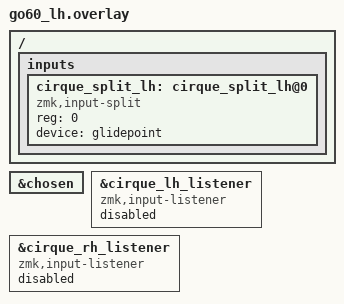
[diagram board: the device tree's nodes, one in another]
/ {
    
    inputs {
        cirque_split_lh: cirque_split_lh@0 {
            compatible = "zmk,input-split";
            reg = <0>;
            device = <&glidepoint>;
        };
    };
};

&chosen {
  /delete-property/ zmk,underglow_indicators;
}
/delete-node/ &underglow_indicators;
/delete-node/ &cirque_split;

// Disabled input listeners for the Cirques, to permit references in the keymap
&cirque_lh_listener {
    compatible = "zmk,input-listener";
    status = "disabled";
    /delete-property/ device;
};


&cirque_rh_listener {
    compatible = "zmk,input-listener";
    status = "disabled";
    /delete-property/ device;
};


